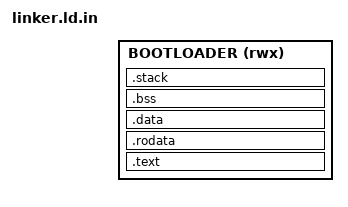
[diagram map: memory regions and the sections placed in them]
ENTRY(_start)

BASE_ADDRESS = @bootloaderAddress@;

MEMORY
{
  BOOTLOADER (rwx) : ORIGIN = @bootloaderAddress@, LENGTH = @bootloaderRegionSize@
}

SECTIONS
{
  . = BASE_ADDRESS;

  .text : {
    KEEP(*(.text.init))
    *(.text .text.*)
  } > BOOTLOADER

  .rodata : {
    *(.srodata .srodata.*)
    *(.rodata .rodata.*)
  } > BOOTLOADER

  .data : {
    . = ALIGN(8);

    __global_pointer$ = . + 0x800;

    *(.sdata .sdata.*)
    *(.data .data.*)
  } > BOOTLOADER

  .bss (NOLOAD) : {
    . = ALIGN(8);

    _bss_start = .;

    *(.sbss .sbss.*)
    *(.bss .bss.*)
    *(COMMON)

    _bss_end = .;
  } > BOOTLOADER

  .stack (NOLOAD) : {
    . = ALIGN(16);

    _stack_start = .;
    . += 16K;
    _stack_end = .;
  } > BOOTLOADER
}
